AUTOSAR XML (schema 00046)
package /ComponentTypes
  swc implementation Ct_MBBL_SsaAppl_General_Implementation: behavior=Ct_MBBL_SsaAppl_General_InternalBehavior
    code-descriptors:
      code Default: artifact-descriptors=autosar-engineering-object=category=SWSRC
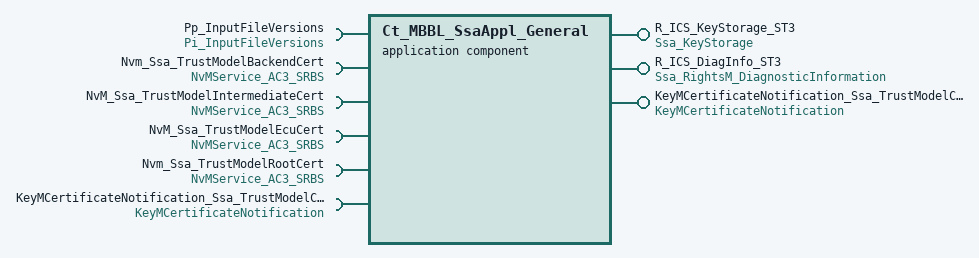
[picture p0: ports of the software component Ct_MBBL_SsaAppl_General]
  application sw component type Ct_MBBL_SsaAppl_General
    provide port R_ICS_KeyStorage_ST3: server-com-spec{operation=StorePermanently, queue-length=1}, provided-interface=Ssa_KeyStorage  # Requests for storing the key material or certificates permanently i.e. for making them persistent.
    provide port R_ICS_DiagInfo_ST3: server-com-spec{operation=Get, queue-length=1}, provided-interface=Ssa_RightsM_DiagnosticInformation
    6 x require port:
      Pp_InputFileVersions: required-interface=Pi_InputFileVersions
        required-com-specs:
          init-value=constant-reference=Const_PI_DiagVariant, parameter=DiagnosticVariant
          init-value=constant-reference=Const_PI_DiagVersion, parameter=DiagnosticVersion
      Nvm_Ssa_TrustModelBackendCert: required-com-specs=[EraseBlock, InvalidateNvBlock, WriteBlock, ReadBlock, SetRamBlockStatus, GetErrorStatus], required-interface=NvMService_AC3_SRBS
      NvM_Ssa_TrustModelIntermediateCert: required-com-specs=[EraseBlock, InvalidateNvBlock, WriteBlock, ReadBlock, SetRamBlockStatus, GetErrorStatus], required-interface=NvMService_AC3_SRBS
      NvM_Ssa_TrustModelEcuCert: required-com-specs=[EraseBlock, InvalidateNvBlock, WriteBlock, ReadBlock, SetRamBlockStatus, GetErrorStatus], required-interface=NvMService_AC3_SRBS
      Nvm_Ssa_TrustModelRootCert: required-com-specs=[GetErrorStatus, SetRamBlockStatus, ReadBlock, WriteBlock, InvalidateNvBlock, EraseBlock], required-interface=NvMService_AC3_SRBS
      KeyMCertificateNotification_Ssa_TrustModelCert_Client: required-com-specs=[ServiceCertificateCallbackNotification, CertificateVerifyCallbackNotification], required-interface=KeyMCertificateNotification
    provide port KeyMCertificateNotification_Ssa_TrustModelCert_Server: provided-interface=KeyMCertificateNotification
      provided-com-specs:
        operation=ServiceCertificateCallbackNotification, queue-length=1
        operation=CertificateVerifyCallbackNotification, queue-length=1
    behavior Ct_MBBL_SsaAppl_General_InternalBehavior
      operation invoked event OIT_R_ICS_DiagInfo_ST3_Get_R_ICS_DiagInfo_ST3_Get: start-on-event=R_ICS_DiagInfo_ST3_Get, operation=R_ICS_DiagInfo_ST3.Get
      operation invoked event OIT_R_ICS_KeyStorage_ST3_StorePermanently_R_ICS_KeyStorage_ST3_StorePermanently: start-on-event=R_ICS_KeyStorage_ST3_StorePermanently, operation=R_ICS_KeyStorage_ST3.StorePermanently
      init event Ct_MBBL_SsaAppl_General_InitEvent: start-on-event=Ct_MBBL_SsaAppl_General_Init
      operation invoked event OIT_KeyMCertificateNotification_Ssa_TrustModelCert_Server_CertificateVerifyCallbackNotification_KeyMCertificateNotificat527E9A1F: start-on-event=KeyMCertificateNotification_Ssa_TrustModelCert_Server_CertificateVerifyCallbackNotification, operation=KeyMCertificateNotification_Ssa_TrustModelCert_Server.CertificateVerifyCallbackNotification
      operation invoked event OIT_KeyMCertificateNotification_Ssa_TrustModelCert_Server_ServiceCertificateCallbackNotification_KeyMCertificateNotifica90AF945E: start-on-event=KeyMCertificateNotification_Ssa_TrustModelCert_Server_ServiceCertificateCallbackNotification, operation=KeyMCertificateNotification_Ssa_TrustModelCert_Server.ServiceCertificateCallbackNotification
      5 x runnable:
        R_ICS_DiagInfo_ST3_Get
        R_ICS_KeyStorage_ST3_StorePermanently: can-be-invoked-concurrently=true
          24 x sync call:
            SC_NvM_Ssa_TrustModelEcuCert_EraseBlock: operation=NvM_Ssa_TrustModelEcuCert.EraseBlock
            SC_NvM_Ssa_TrustModelEcuCert_GetErrorStatus: operation=NvM_Ssa_TrustModelEcuCert.GetErrorStatus
            SC_NvM_Ssa_TrustModelEcuCert_InvalidateNvBlock: operation=NvM_Ssa_TrustModelEcuCert.InvalidateNvBlock
            SC_NvM_Ssa_TrustModelEcuCert_ReadBlock: operation=NvM_Ssa_TrustModelEcuCert.ReadBlock
            SC_NvM_Ssa_TrustModelEcuCert_SetRamBlockStatus: operation=NvM_Ssa_TrustModelEcuCert.SetRamBlockStatus
            SC_NvM_Ssa_TrustModelEcuCert_WriteBlock: operation=NvM_Ssa_TrustModelEcuCert.WriteBlock
            SC_NvM_Ssa_TrustModelIntermediateCert_EraseBlock: operation=NvM_Ssa_TrustModelIntermediateCert.EraseBlock
            SC_NvM_Ssa_TrustModelIntermediateCert_GetErrorStatus: operation=NvM_Ssa_TrustModelIntermediateCert.GetErrorStatus
            SC_NvM_Ssa_TrustModelIntermediateCert_InvalidateNvBlock: operation=NvM_Ssa_TrustModelIntermediateCert.InvalidateNvBlock
            SC_NvM_Ssa_TrustModelIntermediateCert_ReadBlock: operation=NvM_Ssa_TrustModelIntermediateCert.ReadBlock
            SC_NvM_Ssa_TrustModelIntermediateCert_SetRamBlockStatus: operation=NvM_Ssa_TrustModelIntermediateCert.SetRamBlockStatus
            SC_NvM_Ssa_TrustModelIntermediateCert_WriteBlock: operation=NvM_Ssa_TrustModelIntermediateCert.WriteBlock
            SC_Nvm_Ssa_TrustModelBackendCert_EraseBlock: operation=Nvm_Ssa_TrustModelBackendCert.EraseBlock
            SC_Nvm_Ssa_TrustModelBackendCert_GetErrorStatus: operation=Nvm_Ssa_TrustModelBackendCert.GetErrorStatus
            SC_Nvm_Ssa_TrustModelBackendCert_InvalidateNvBlock: operation=Nvm_Ssa_TrustModelBackendCert.InvalidateNvBlock
            SC_Nvm_Ssa_TrustModelBackendCert_ReadBlock: operation=Nvm_Ssa_TrustModelBackendCert.ReadBlock
            SC_Nvm_Ssa_TrustModelBackendCert_SetRamBlockStatus: operation=Nvm_Ssa_TrustModelBackendCert.SetRamBlockStatus
            SC_Nvm_Ssa_TrustModelBackendCert_WriteBlock: operation=Nvm_Ssa_TrustModelBackendCert.WriteBlock
            SC_Nvm_Ssa_TrustModelRootCert_EraseBlock: operation=Nvm_Ssa_TrustModelRootCert.EraseBlock
            SC_Nvm_Ssa_TrustModelRootCert_GetErrorStatus: operation=Nvm_Ssa_TrustModelRootCert.GetErrorStatus
            SC_Nvm_Ssa_TrustModelRootCert_InvalidateNvBlock: operation=Nvm_Ssa_TrustModelRootCert.InvalidateNvBlock
            SC_Nvm_Ssa_TrustModelRootCert_ReadBlock: operation=Nvm_Ssa_TrustModelRootCert.ReadBlock
            SC_Nvm_Ssa_TrustModelRootCert_SetRamBlockStatus: operation=Nvm_Ssa_TrustModelRootCert.SetRamBlockStatus
            SC_Nvm_Ssa_TrustModelRootCert_WriteBlock: operation=Nvm_Ssa_TrustModelRootCert.WriteBlock
        Ct_MBBL_SsaAppl_General_Init
        KeyMCertificateNotification_Ssa_TrustModelCert_Server_CertificateVerifyCallbackNotification
        KeyMCertificateNotification_Ssa_TrustModelCert_Server_ServiceCertificateCallbackNotification
